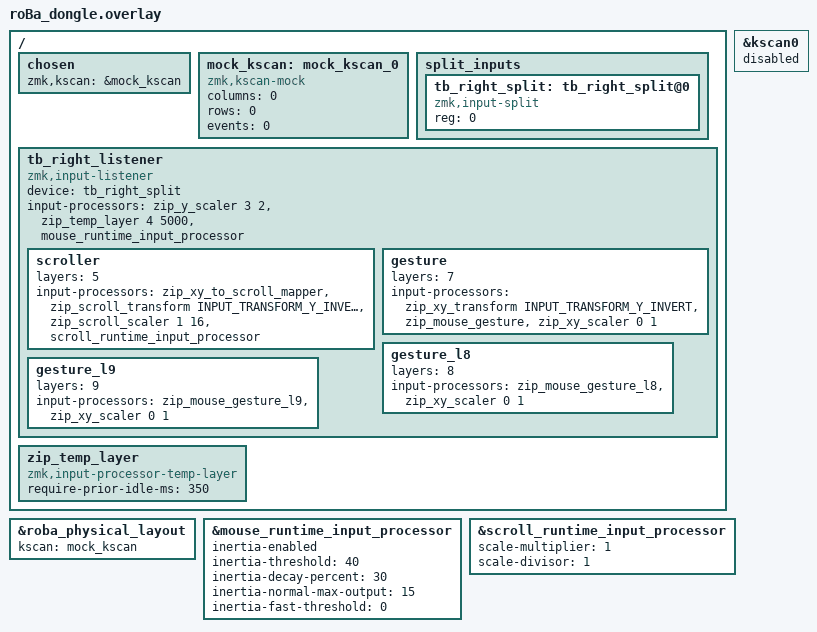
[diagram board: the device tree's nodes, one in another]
#include <dt-bindings/zmk/input_transform.h>
#include <input/processors.dtsi>
#include <input/processors/runtime-input-processor.dtsi>
#include <behaviors/battery_history_request.dtsi>
// 物理レイアウト（Studio 用）・マトリクス・エンコーダー定義を左右と共通化
#include "roBa.dtsi"

// ドングルにキーは無いので mock kscan を使う
&kscan0 { status = "disabled"; };
&roba_physical_layout {
    kscan = <&mock_kscan>;
};

/ {
    chosen {
        zmk,kscan = &mock_kscan;
    };

    mock_kscan: mock_kscan_0 {
        compatible = "zmk,kscan-mock";
        columns = <0>;
        rows = <0>;
        events = <0>;
    };

    split_inputs {
        #address-cells = <1>;
        #size-cells = <0>;
        tb_right_split: tb_right_split@0 {
            compatible = "zmk,input-split";
            reg = <0>;
        };
    };

    // Y軸はペリフェラル側で反転済みのため、roBa_R.overlay と向きを揃える
    tb_right_listener: tb_right_listener {
        compatible = "zmk,input-listener";
        status = "okay";
        device = <&tb_right_split>;
        input-processors = <&zip_y_scaler 3 2 &zip_temp_layer 4 5000 &mouse_runtime_input_processor>;
        scroller {
            layers = <5>;
            input-processors = <
                &zip_xy_to_scroll_mapper
                &zip_scroll_transform INPUT_TRANSFORM_Y_INVERT
                &zip_scroll_scaler 1 16
                &scroll_runtime_input_processor
            >;
        };
        gesture {
            layers = <7>;
            input-processors = <&zip_xy_transform INPUT_TRANSFORM_Y_INVERT &zip_mouse_gesture &zip_xy_scaler 0 1>;
        };
        gesture_l8 {
            layers = <8>;
            input-processors = <&zip_mouse_gesture_l8 &zip_xy_scaler 0 1>;
        };
        gesture_l9 {
            layers = <9>;
            input-processors = <&zip_mouse_gesture_l9 &zip_xy_scaler 0 1>;
        };
    };

    /omit-if-no-ref/ zip_temp_layer: zip_temp_layer {
        compatible = "zmk,input-processor-temp-layer";
        #input-processor-cells = <2>;
        require-prior-idle-ms = <350>;
    };
};

// ポインタにほんの少しだけ慣性をつける（素早く弾いたときだけ、短い余韻で止まる）
&mouse_runtime_input_processor {
    inertia-enabled;
    inertia-threshold = <40>;
    inertia-decay-percent = <30>;
    inertia-normal-max-output = <15>;
    inertia-fast-threshold = <0>;
};

// runtime-input-processor の scroll 既定値は 1/60。zip_scroll_scaler と重なるため等倍にする
&scroll_runtime_input_processor {
    scale-multiplier = <1>;
    scale-divisor = <1>;
};
